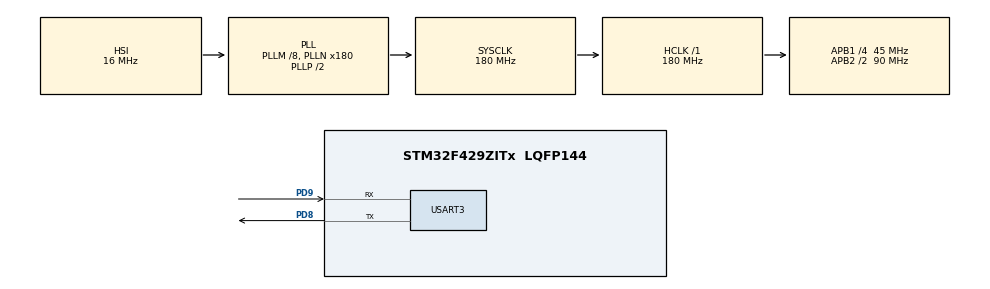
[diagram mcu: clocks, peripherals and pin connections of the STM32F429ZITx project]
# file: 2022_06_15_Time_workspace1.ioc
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Mcu.Family=STM32F4
Mcu.Name=STM32F429ZITx
Mcu.Package=LQFP144
NVIC.PriorityGroup=NVIC_PRIORITYGROUP_4
PA13.Mode=Serial_Wire
PA13.Signal=SYS_JTMS-SWDIO
PA14.Mode=Serial_Wire
PA14.Signal=SYS_JTCK-SWCLK
PC14/OSC32_IN.Mode=LSE-External-Oscillator
PC14/OSC32_IN.Signal=RCC_OSC32_IN
PC15/OSC32_OUT.Mode=LSE-External-Oscillator
PC15/OSC32_OUT.Signal=RCC_OSC32_OUT
PD8.Mode=Asynchronous
PD8.Signal=USART3_TX
PD9.Mode=Asynchronous
PD9.Signal=USART3_RX
ProjectManager.HeapSize=0x200
ProjectManager.StackSize=0x400
ProjectManager.TargetToolchain=STM32CubeIDE
RCC.48MHZClocksFreq_Value=90000000
RCC.AHBFreq_Value=180000000
RCC.APB1CLKDivider=RCC_HCLK_DIV4
RCC.APB1Freq_Value=45000000
RCC.APB1TimFreq_Value=90000000
RCC.APB2CLKDivider=RCC_HCLK_DIV2
RCC.APB2Freq_Value=90000000
RCC.APB2TimFreq_Value=180000000
RCC.CortexFreq_Value=180000000
RCC.HCLKFreq_Value=180000000
RCC.HSE_VALUE=25000000
RCC.HSI_VALUE=16000000
RCC.PLLM=8
RCC.PLLN=180
RCC.RCC_RTC_Clock_Source=RCC_RTCCLKSOURCE_LSE
RCC.RCC_RTC_Clock_SourceVirtual=RCC_RTCCLKSOURCE_LSE
RCC.SYSCLKFreq_VALUE=180000000
RCC.SYSCLKSource=RCC_SYSCLKSOURCE_PLLCLK
RCC.VCOOutputFreq_Value=360000000
TIM3.Period=900
TIM3.Prescaler=1000
USART3.VirtualMode=VM_ASYNC
VP_RTC_VS_RTC_Activate.Mode=RTC_Enabled
VP_TIM3_VS_ClockSourceINT.Mode=Internal
board=custom

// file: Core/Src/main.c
/* USER CODE BEGIN Header */
/**
  ******************************************************************************
  * @file           : main.c
  * @brief          : Main program body
  ******************************************************************************
  * @attention
  *
  * Copyright (c) 2022 STMicroelectronics.
  * All rights reserved.
  *
  * This software is licensed under terms that can be found in the LICENSE file
  * in the root directory of this software component.
  * If no LICENSE file comes with this software, it is provided AS-IS.
  *
  ******************************************************************************
  */
/* USER CODE END Header */
#include "main.h"
#include "rtc.h"
#include "tim.h"
#include "usart.h"
#include "gpio.h"

/* USER CODE BEGIN Includes */
#include <string.h>
#include <stdio.h>

/* USER CODE END Includes */

void SystemClock_Config(void);

/* USER CODE BEGIN 0 */
RTC_TimeTypeDef sTime = {0};
RTC_DateTypeDef sDate = {0};
int uart_buf;
/* USER CODE END 0 */

int main(void)
{
  /* USER CODE BEGIN 1 */
  char temp[100];
  char ampm[2][3] = {"AM", "PM"};

  uint32_t *flash_addr;

  /* USER CODE END 1 */

  /* MCU Configuration--------------------------------------------------------*/

  /* Reset of all peripherals, Initializes the Flash interface and the Systick. */
  HAL_Init();

  /* Configure the system clock */
  SystemClock_Config();

  /* Initialize all configured peripherals */
  MX_GPIO_Init();
  MX_USART3_UART_Init();
  MX_RTC_Init();
  MX_TIM3_Init();
  /* USER CODE BEGIN 2 */

  sTime.Hours = 11;
  sTime.Minutes = 18;
  sTime.Seconds = 30;
  sDate.Date = 20;

/*
  HAL_RTC_SetTime(&hrtc, &sTime, RTC_FORMAT_BIN);
  HAL_RTC_SetDate(&hrtc, &sDate, RTC_FORMAT_BIN);*/

  flash_addr = (uint32_t *) 0x080000000;

  for(int i = 0; i< 10 ; i++){
	  memset(uart_buf, 0, sizeof(uart_buf));
	  sprint(uart_buf,"%08X => %08X\r\n", flash_addr, *(flash_addr));
	  HAL_UART_Transmit(&huart3, uart_buf, sizeof(uart_buf),100);
	  flash_addr++;
  }
  /* USER CODE END 2 */

  /* Infinite loop */
  /* USER CODE BEGIN WHILE */
  while (1)
  {
	  HAL_RTC_GetDate(&hrtc, &sDate, RTC_FORMAT_BIN); // 날짜 정보 얻어오기
	  HAL_RTC_GetTime(&hrtc, &sTime, RTC_FORMAT_BIN); // 시간 정보 얻어오기
	  sprintf(temp,"\r\n20%02d-%02d-%02d %s %02d:%02d:%02d", sDate.Year, sDate.Month,
	         sDate.Date, ampm[sTime.TimeFormat], sTime.Hours, sTime.Minutes,
	         sTime.Seconds);
	  HAL_UART_Transmit(&huart3, (uint8_t*)temp, strlen(temp), 1000);

    /* USER CODE END WHILE */

  }
}

void SystemClock_Config(void)
{
  RCC_OscInitTypeDef RCC_OscInitStruct = {0};
  RCC_ClkInitTypeDef RCC_ClkInitStruct = {0};

  /** Configure the main internal regulator output voltage
  */
  __HAL_RCC_PWR_CLK_ENABLE();
  __HAL_PWR_VOLTAGESCALING_CONFIG(PWR_REGULATOR_VOLTAGE_SCALE1);

  /** Initializes the RCC Oscillators according to the specified parameters
  * in the RCC_OscInitTypeDef structure.
  */
  RCC_OscInitStruct.OscillatorType = RCC_OSCILLATORTYPE_HSI|RCC_OSCILLATORTYPE_LSE;
  RCC_OscInitStruct.LSEState = RCC_LSE_ON;
  RCC_OscInitStruct.HSIState = RCC_HSI_ON;
  RCC_OscInitStruct.HSICalibrationValue = RCC_HSICALIBRATION_DEFAULT;
  RCC_OscInitStruct.PLL.PLLState = RCC_PLL_ON;
  RCC_OscInitStruct.PLL.PLLSource = RCC_PLLSOURCE_HSI;
  RCC_OscInitStruct.PLL.PLLM = 8;
  RCC_OscInitStruct.PLL.PLLN = 180;
  RCC_OscInitStruct.PLL.PLLP = RCC_PLLP_DIV2;
  RCC_OscInitStruct.PLL.PLLQ = 4;
  if (HAL_RCC_OscConfig(&RCC_OscInitStruct) != HAL_OK)
  {
    Error_Handler();
  }

  /** Activate the Over-Drive mode
  */
  if (HAL_PWREx_EnableOverDrive() != HAL_OK)
  {
    Error_Handler();
  }

  /** Initializes the CPU, AHB and APB buses clocks
  */
  RCC_ClkInitStruct.ClockType = RCC_CLOCKTYPE_HCLK|RCC_CLOCKTYPE_SYSCLK
                              |RCC_CLOCKTYPE_PCLK1|RCC_CLOCKTYPE_PCLK2;
  RCC_ClkInitStruct.SYSCLKSource = RCC_SYSCLKSOURCE_PLLCLK;
  RCC_ClkInitStruct.AHBCLKDivider = RCC_SYSCLK_DIV1;
  RCC_ClkInitStruct.APB1CLKDivider = RCC_HCLK_DIV4;
  RCC_ClkInitStruct.APB2CLKDivider = RCC_HCLK_DIV2;

  if (HAL_RCC_ClockConfig(&RCC_ClkInitStruct, FLASH_LATENCY_5) != HAL_OK)
  {
    Error_Handler();
  }
}

void Error_Handler(void)
{
  __disable_irq();
  while (1)
  {
  }
}
